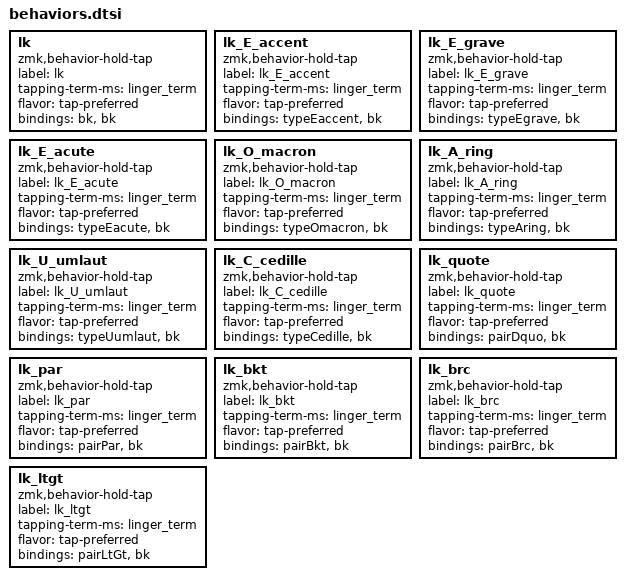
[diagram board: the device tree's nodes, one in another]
/******************** Linger Keys **********************/
lk: lk {
    compatible = "zmk,behavior-hold-tap";
    label = "lk";
    #binding-cells = <2>;
    tapping-term-ms = <linger_term>;
    flavor = "tap-preferred";
    bindings = <&bk>, <&bk>;
};

LK(qu, &Qu, &bk)
LK(th, &Th, &tion)
LK(sh, &Sh, &sion)
LK(gh, &Gh, &ght)

#define tabAlttab &lk LA(TAB) TAB
#define tabCmdtab &lk LG(TAB) TAB

LK(magicArrowL, &arrowLeftSingle, &arrowLeftDouble)
LK(magicArrowR, &arrowRightSingle, &arrowRightDouble)
#define magicArrowL  &lk_magicArrowL XXX XXX
#define magicArrowR  &lk_magicArrowR XXX XXX

LK(bk, &bk, &bk)
#define sqtDqt  &lk_bk DQT SQT
#define equalDash  &lk_bk MINUS EQUAL

LK(magicCloseQuit, &closeTab, &quitApp)
LK(magicCloseQuitLinWin, &closeTabLinWin, &quitAppLinWin)
#define magicCloseQuit  &lk_magicCloseQuit XXX XXX
#define magicCloseQuitLinWin  &lk_magicCloseQuitLinWin XXX XXX

LK(magicSwitchSpaceL, &switchSpaceLinwinL, &switchSpaceL_toBase)
LK(magicSwitchSpaceR, &switchSpaceR,       &switchSpaceR_toLinwin)
#define magicSwitchSpaceL  &lk_magicSwitchSpaceL XXX XXX
#define magicSwitchSpaceR  &lk_magicSwitchSpaceR XXX XXX
/*
Behavior of magicSwitchSpace
============================

SwitchSpaceL: <- That's the 'reset' logic
- on tap: switch to space left
- on linger: switch to space left AND '&to l_alpha'

SwitchSpaceR: <- That's the 'switch to linwin' logic
- on tap: switch to space right
- on linger: switch to space right AND '&to l_alpha_linwin'

*/



// TODO: Make the repeat macro take 1 param, so I can then just define a bunch of: #define lkr_X &lrk F F
// TYPING_MACRO(repeatF, &kp F &kp F)
// TYPING_MACRO(singleF, &kp F)
// LK(repeat, &ak, &repeatF)
// lk_repeat: lk_repeat {
//     compatible = "zmk,behavior-hold-tap";
//     label = "lk_repeat";
//     #binding-cells = <3>;
//     tapping-term-ms = <linger_term>;
//     flavor = "tap-preferred";
//     bindings = <&repeatF>, <&ak>;
// };
// #define lkr_F &lk_repeat XXX <l_akF F>
// #define lkr_F &lk_repeat XXX l_akF F
// #define ak_H &ak l_akH H

// Working, for non-AK keys
TYPING_MACRO(repeatF, &kp F &kp F)
TYPING_MACRO(singleF, &kp F)
LK(repeat, &bk, &repeatF)
#define lkr_F &lk_repeat XXX F

// NOTE: Maybe I just accept that it only works with non-ak keys (for now?)








//********************** UNUSED AT THE MOMENT **********************//
lk_E_accent: lk_E_accent { // ´, é on "linger"
    compatible = "zmk,behavior-hold-tap";
    label = "lk_E_accent";
    #binding-cells = <2>;
    tapping-term-ms = <linger_term>;
    flavor = "tap-preferred";
    bindings = <&typeEaccent>, <&bk>;
};
lk_E_grave: lk_E_grave { // `, è on "linger"
    compatible = "zmk,behavior-hold-tap";
    label = "lk_E_grave";
    #binding-cells = <2>;
    tapping-term-ms = <linger_term>;
    flavor = "tap-preferred";
    bindings = <&typeEgrave>, <&bk>;
};
lk_E_acute: lk_E_acute { // ˆ, ê on "linger"
    compatible = "zmk,behavior-hold-tap";
    label = "lk_E_acute";
    #binding-cells = <2>;
    tapping-term-ms = <linger_term>;
    flavor = "tap-preferred";
    bindings = <&typeEacute>, <&bk>;
};
lk_O_macron: lk_O_macron { // ¯, ō on "linger"
    compatible = "zmk,behavior-hold-tap";
    label = "lk_O_macron";
    #binding-cells = <2>;
    tapping-term-ms = <linger_term>;
    flavor = "tap-preferred";
    bindings = <&typeOmacron>, <&bk>;
};
lk_A_ring: lk_A_ring { // ˚, å on "linger"
    compatible = "zmk,behavior-hold-tap";
    label = "lk_A_ring";
    #binding-cells = <2>;
    tapping-term-ms = <linger_term>;
    flavor = "tap-preferred";
    bindings = <&typeAring>, <&bk>;
};
lk_U_umlaut: lk_U_umlaut { // ¨, ü on "linger"
    compatible = "zmk,behavior-hold-tap";
    label = "lk_U_umlaut";
    #binding-cells = <2>;
    tapping-term-ms = <linger_term>;
    flavor = "tap-preferred";
    bindings = <&typeUumlaut>, <&bk>;
};
lk_C_cedille: lk_C_cedille { // ¸, ç on "linger"
    compatible = "zmk,behavior-hold-tap";
    label = "lk_C_cedille";
    #binding-cells = <2>;
    tapping-term-ms = <linger_term>;
    flavor = "tap-preferred";
    bindings = <&typeCedille>, <&bk>;
};


lk_quote: lk_quote { // " on tap, “” on "linger" (curly quotes)
    compatible = "zmk,behavior-hold-tap";
    label = "lk_quote";
    #binding-cells = <2>;
    tapping-term-ms = <linger_term>;
    flavor = "tap-preferred";
    bindings = <&pairDquo>, <&bk>;
};
lk_par: lk_par { // ( on tap, () on "linger"
    compatible = "zmk,behavior-hold-tap";
    label = "lk_par";
    #binding-cells = <2>;
    tapping-term-ms = <linger_term>;
    flavor = "tap-preferred";
    bindings = <&pairPar>, <&bk>;
};
lk_bkt: lk_bkt { // [ on tap, [] on "linger"
    compatible = "zmk,behavior-hold-tap";
    label = "lk_bkt";
    #binding-cells = <2>;
    tapping-term-ms = <linger_term>;
    flavor = "tap-preferred";
    bindings = <&pairBkt>, <&bk>;
};
lk_brc: lk_brc { // { on tap, {} on "linger"
    compatible = "zmk,behavior-hold-tap";
    label = "lk_brc";
    #binding-cells = <2>;
    tapping-term-ms = <linger_term>;
    flavor = "tap-preferred";
    bindings = <&pairBrc>, <&bk>;
};
lk_ltgt: lk_ltgt { // < on tap, <|> on "linger"
    compatible = "zmk,behavior-hold-tap";
    label = "lk_ltgt";
    #binding-cells = <2>;
    tapping-term-ms = <linger_term>;
    flavor = "tap-preferred";
    bindings = <&pairLtGt>, <&bk>;
};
